# LPC178x7x register map
File version: 0.9-mod
CPU: CM3 r0p0, little endian, no MPU, no FPU, 3 interrupt priority bits
Registers are 32-bit, read-write, reset 0x0 unless marked. A register's access mark holds for its fields unless they carry their own. Offsets are from the block's base; [hi:lo] are bit positions; {n}, {i} and the like mark numbered series.

## FLASHCTRL — Flash control block
Base 0x00200000
0x20 FMSSTART — Signature start address register
  [16:0] START — Signature generation start address (corresponds to AHB byte address bits[20:4]).
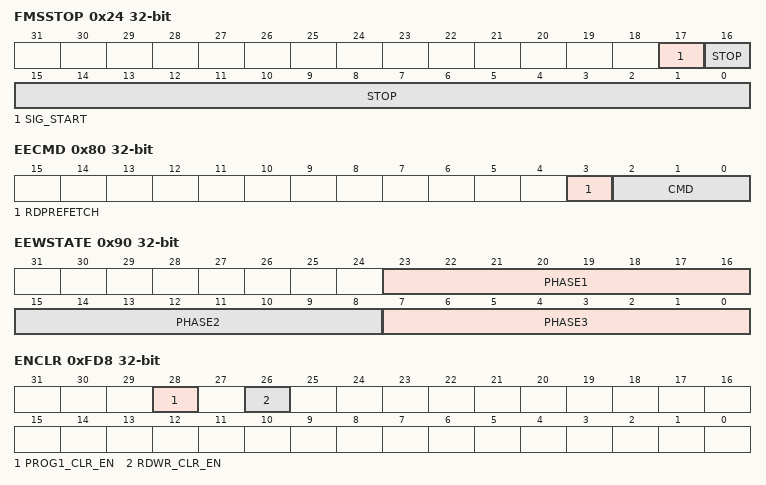
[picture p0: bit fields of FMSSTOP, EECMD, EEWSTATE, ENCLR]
0x24 FMSSTOP — Signature stop-address register
  [17] SIG_START — Start control bit for signature generation.
    0=STOP (Signature generation is stopped); 1=START (Initiate signature generation)
  [16:0] STOP — BIST stop address divided by 16 (corresponds to AHB byte address [20:4]).
{0x2C+4i} FMSW{i} ro reset not defined (i=0..3) — 128-bit signature Word {i}
  [31:0] SW{i}_{32i+31}_{32i} — Word {i} of 128-bit signature (bits {32i+31} to {32i}).
0x80 EECMD — EEPROM command register
  [3] RDPREFETCH — Read data prefetch bit. 0: do not prefetch next read data as result of reading from the read data register. 1: prefetch read data as result of reading from the read data register. When this bit is set multiple consecutive data elements can be read without the need of programming new address values in the address register. The address post-increment and the automatic read data prefetch (if enabled) allow only reading from the read data register to be done to read the data.
  [2:0] CMD — Command. 000: 8-bit read 001: 16-bit read 010: 32-bit read 011: 8-bit write 100: 16-bit write 101: 32-bit write 110: erase/program page 111: reserved
0x84 EEADDR — EEPROM address register
  [11:0] ADDR — EEPROM Address. Lower 6 bits are don't care.
0x88 EEWDATA wo reset not defined — EEPROM write data register
  [31:0] WDATA — Write data. In case of: 8-bit write operations: bits [7:0] must contain valid write data. 16-bit write operations: bits [15:0] must contain valid write data. 32-bit write operations: bits [31:0] must contain valid write data.
0x8C EERDATA ro reset not defined — EEPROM read data register
  [31:0] RDATA — Read data. In case of: 8-bit read operations: bits [7:0] contain read data, others are zero. 16-bit read operations: bits [15:0] contain read data, others are zero. 32-bit read operations: bits [31:0] contain read data.
0x90 EEWSTATE — EEPROM wait state register
  [23:16] PHASE1 — Wait states 1 (minus 1 encoded). The number of system clock periods required to give a minimum time of 35 ns.
  [15:8] PHASE2 — Wait states 2 (minus 1 encoded). The number of system clock periods required to give a minimum time of 55 ns.
  [7:0] PHASE3 — Wait states 3 (minus 1 encoded). The number of system clock periods required to give a minimum time of 15 ns.
0x94 EECLKDIV — EEPROM clock divider register
  [15:0] CLKDIV — Division factor (minus 1 encoded).
0x98 EEPWRDWN — EEPROM power-down register
  [0] PWRDWN — Power down mode bit. 0: not in power down mode. 1: power down mode (this will put all EEPROM devices in power down).
0xFD8 ENCLR wo — EEPROM interrupt enable clear
  [28] PROG1_CLR_EN — Clear program operation finished interrupt enable bit for EEPROM device 1. 0: leave corresponding bit unchanged. 1: clear corresponding bit.
  [26] RDWR_CLR_EN — Clear read/write operation finished interrupt enable bit (EEPROM). 0: leave corresponding bit unchanged. 1: clear corresponding bit.
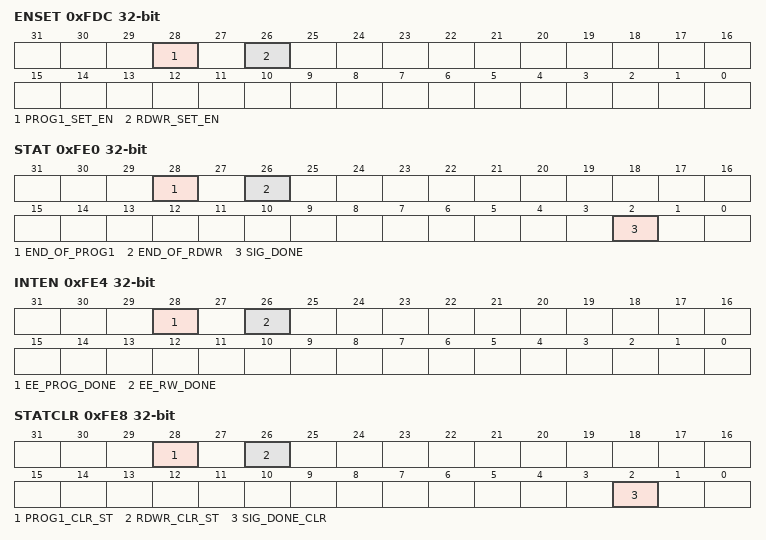
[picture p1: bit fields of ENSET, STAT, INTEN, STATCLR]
0xFDC ENSET wo — EEPROM interrupt enable set
  [28] PROG1_SET_EN — Set program operation finished interrupt enable bit for EEPROM device 1. 0: leave corresponding bit unchanged. 1: set corresponding bit.
  [26] RDWR_SET_EN — Set read/write operation finished interrupt enable bit (EEPROM). 0: leave corresponding bit unchanged. 1: set corresponding bit.
0xFE0 STAT ro — Signature generation status register
  [28] END_OF_PROG1 — EEPROM program operation finished interrupt status bit. Bit is: - set when this operation has finished OR when 1 is written to the corresponding bit of the EEINTSTATSET register. - cleared when 1 is written to the corresponding bit of the EEINTSTATCLR register.
  [26] END_OF_RDWR — EEPROM read/write operation finished interrupt status bit. Bit is: - set when this operation has finished OR when 1 is written in the corresponding bit of the EEINTSTATSET register. - cleared when 1 is written to the corresponding bit of the EEINTSTATCLR register.
  [2] SIG_DONE — When 1, a previously started signature generation has completed. See FMSTATCLR register description for clearing this flag.
0xFE4 INTEN ro — EEPROM interrupt enable
  [28] EE_PROG_DONE — EEPROM program operation finished interrupt enable bit. Bit is: - set when 1 is written in the corresponding bit of the EEINTENSET register. - cleared when 1 is written to the corresponding bit of the EEINTENCLR register.
  [26] EE_RW_DONE — EEPROM read/write operation finished interrupt enable bit. Bit is: - set when 1 is written to the corresponding bit of the EEINTENSET register. - cleared when 1 is written to the corresponding bit of the EEINTENCLR register.
0xFE8 STATCLR wo reset not defined — Signature generation status clear register
  [28] PROG1_CLR_ST — Clear program operation finished interrupt status bit for EEPROM device 1. 0 leave corresponding bit unchanged. 1 clear corresponding bit.
  [26] RDWR_CLR_ST — Clear read/write operation finished interrupt status bit (EEPROM). 0 leave corresponding bit unchanged. 1 clear corresponding bit.
  [2] SIG_DONE_CLR — Writing a 1 to this bits clears the signature generation completion flag (SIG_DONE) in the FMSTAT register.
